# PIC32MM0064GPM036 device description
Architecture: MIPS; Family: PIC32MM1387; Series: PIC32MM
Registers are 32-bit, read-write, no defined reset value unless marked. A register's access mark holds for its fields unless they carry their own. Offsets are from the block's base; [hi:lo] are bit positions; lines under a group give offsets from that group; {n}, {i} and the like mark numbered series.

## INT
Instances: INT 0x1f802910 in periph0
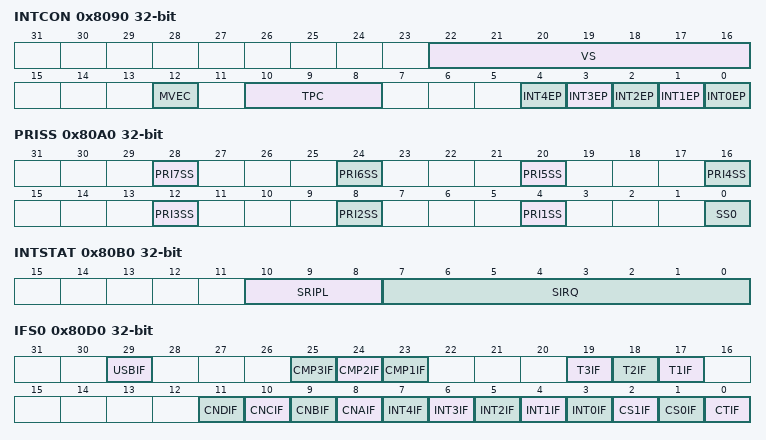
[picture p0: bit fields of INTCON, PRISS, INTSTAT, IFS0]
0x8090 INTCON — Interrupt Control Register
  [22:16] VS
  [12] MVEC — Multi Vector Configuration bit
    1=Interrupt controller configured for multi vectored mode; 0=Interrupt controller configured for single vectored mode
  [10:8] TPC — Interrupt Proximity Timer Control bits
    {v}=Interrupts of group priority {v} or lower start the Interrupt Proximity timer (v=2..7); 1=Interrupts of group priority 1 start the Interrupt Proximity timer; 0=Disables Interrupt Proximity timer
  [n] INT{n}EP (n=0..4) — External Interrupt {n} Edge
    1=Rising edge; 0=Falling edge
0x80A0 PRISS
  [4n] PRI{n}SS (n=1..7)
  [0] SS0 — Single Vector Shadow Register Set bit
    1=Single vector is presented with a shadow register set; 0=Single vector is not presented with a shadow register set
0x80B0 INTSTAT ro — Interrupt Status Register
  [10:8] SRIPL, [7:0] SIRQ
0x80C0 IPTMR
0x80D0 IFS0
  [29] USBIF, [25] CMP3IF, [24] CMP2IF, [23] CMP1IF, [19] T3IF, [18] T2IF, [17] T1IF, [11] CNDIF, [10] CNCIF, [9] CNBIF, [8] CNAIF, [n+3] INT{n}IF (n=0..4), [2] CS1IF, [1] CS0IF, [0] CTIF
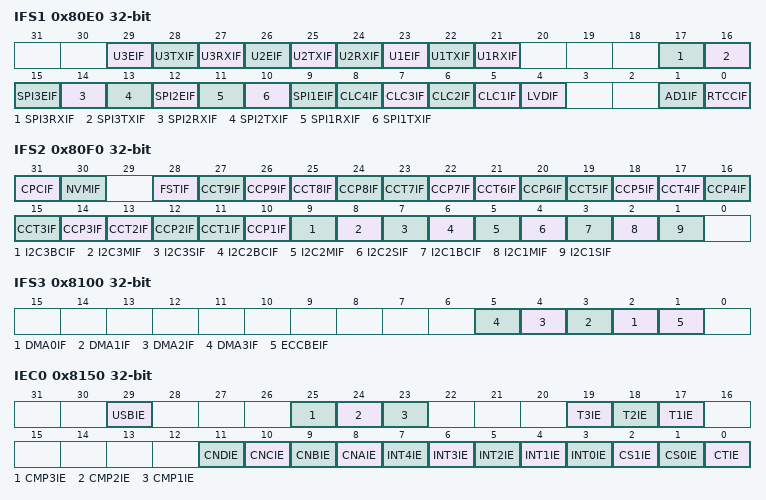
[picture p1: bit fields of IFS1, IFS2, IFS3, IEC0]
0x80E0 IFS1
  [29] U3EIF, [28] U3TXIF, [27] U3RXIF, [26] U2EIF, [25] U2TXIF, [24] U2RXIF, [23] U1EIF, [22] U1TXIF, [21] U1RXIF, [17] SPI3RXIF, [16] SPI3TXIF, [15] SPI3EIF, [14] SPI2RXIF, [13] SPI2TXIF, [12] SPI2EIF, [11] SPI1RXIF, [10] SPI1TXIF, [9] SPI1EIF, [n+4] CLC{n}IF (n=1..4), [4] LVDIF, [1] AD1IF, [0] RTCCIF
0x80F0 IFS2
  [31] CPCIF, [30] NVMIF, [28] FSTIF, [2n+9] CCT{n}IF (n=1..9), [2n+8] CCP{n}IF (n=1..9), [9] I2C3BCIF, [8] I2C3MIF, [7] I2C3SIF, [6] I2C2BCIF, [5] I2C2MIF, [4] I2C2SIF, [3] I2C1BCIF, [2] I2C1MIF, [1] I2C1SIF
0x8100 IFS3
  [n+2] DMA{n}IF (n=0..3), [1] ECCBEIF
0x8150 IEC0
  [29] USBIE, [25] CMP3IE, [24] CMP2IE, [23] CMP1IE, [19] T3IE, [18] T2IE, [17] T1IE, [11] CNDIE, [10] CNCIE, [9] CNBIE, [8] CNAIE, [n+3] INT{n}IE (n=0..4), [2] CS1IE, [1] CS0IE, [0] CTIE
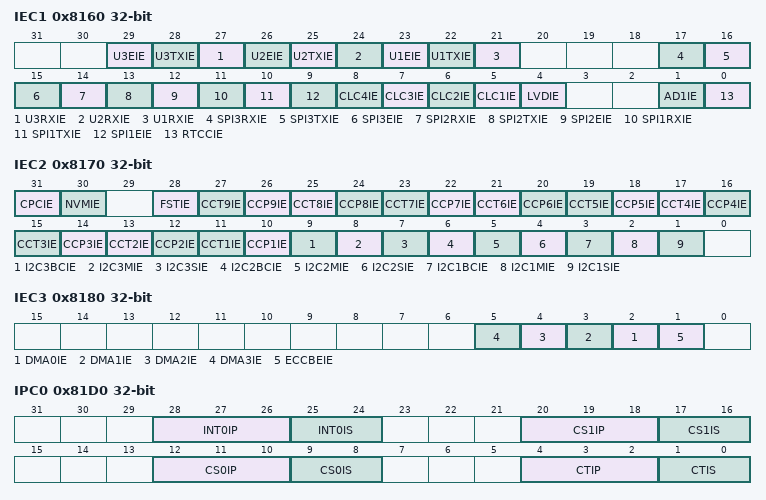
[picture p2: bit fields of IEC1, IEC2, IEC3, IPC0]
0x8160 IEC1
  [29] U3EIE, [28] U3TXIE, [27] U3RXIE, [26] U2EIE, [25] U2TXIE, [24] U2RXIE, [23] U1EIE, [22] U1TXIE, [21] U1RXIE, [17] SPI3RXIE, [16] SPI3TXIE, [15] SPI3EIE, [14] SPI2RXIE, [13] SPI2TXIE, [12] SPI2EIE, [11] SPI1RXIE, [10] SPI1TXIE, [9] SPI1EIE, [n+4] CLC{n}IE (n=1..4), [4] LVDIE, [1] AD1IE, [0] RTCCIE
0x8170 IEC2
  [31] CPCIE, [30] NVMIE, [28] FSTIE, [2n+9] CCT{n}IE (n=1..9), [2n+8] CCP{n}IE (n=1..9), [9] I2C3BCIE, [8] I2C3MIE, [7] I2C3SIE, [6] I2C2BCIE, [5] I2C2MIE, [4] I2C2SIE, [3] I2C1BCIE, [2] I2C1MIE, [1] I2C1SIE
0x8180 IEC3
  [n+2] DMA{n}IE (n=0..3), [1] ECCBEIE
0x81D0 IPC0
  [28:26] INT0IP, [25:24] INT0IS, [20:18] CS1IP, [17:16] CS1IS, [12:10] CS0IP, [9:8] CS0IS, [4:2] CTIP, [1:0] CTIS
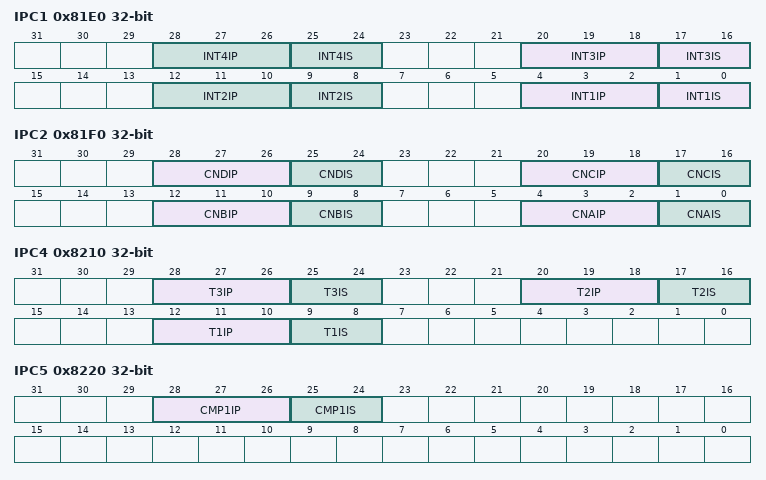
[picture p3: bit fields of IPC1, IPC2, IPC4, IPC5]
0x81E0 IPC1
  [8n-4:8n-6] INT{n}IP (n=1..4), [8n-7:8n-8] INT{n}IS (n=1..4)
0x81F0 IPC2
  [28:26] CNDIP, [25:24] CNDIS, [20:18] CNCIP, [17:16] CNCIS, [12:10] CNBIP, [9:8] CNBIS, [4:2] CNAIP, [1:0] CNAIS
0x8200 IPC3 ro
0x8210 IPC4
  [28:26] T3IP, [25:24] T3IS, [20:18] T2IP, [17:16] T2IS, [12:10] T1IP, [9:8] T1IS
0x8220 IPC5
  [28:26] CMP1IP, [25:24] CMP1IS
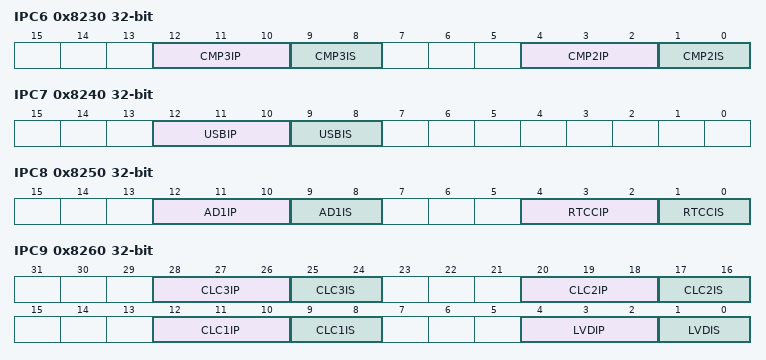
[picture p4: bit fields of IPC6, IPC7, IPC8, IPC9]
0x8230 IPC6
  [12:10] CMP3IP, [9:8] CMP3IS, [4:2] CMP2IP, [1:0] CMP2IS
0x8240 IPC7
  [12:10] USBIP, [9:8] USBIS
0x8250 IPC8
  [12:10] AD1IP, [9:8] AD1IS, [4:2] RTCCIP, [1:0] RTCCIS
0x8260 IPC9
  [28:26] CLC3IP, [25:24] CLC3IS, [20:18] CLC2IP, [17:16] CLC2IS, [12:10] CLC1IP, [9:8] CLC1IS, [4:2] LVDIP, [1:0] LVDIS
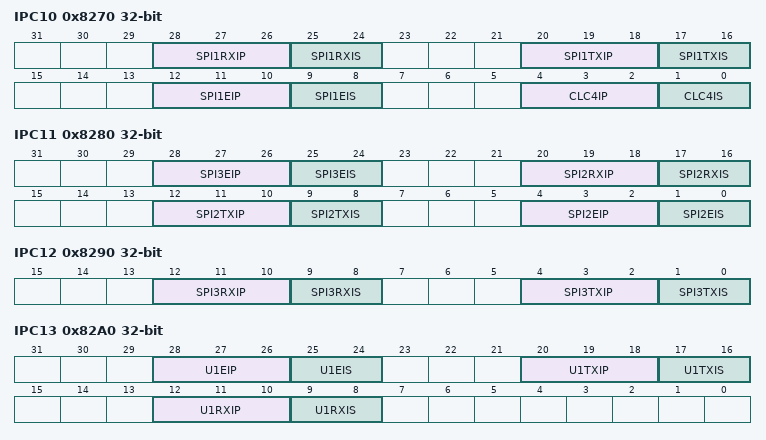
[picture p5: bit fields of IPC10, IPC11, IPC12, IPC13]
0x8270 IPC10
  [28:26] SPI1RXIP, [25:24] SPI1RXIS, [20:18] SPI1TXIP, [17:16] SPI1TXIS, [12:10] SPI1EIP, [9:8] SPI1EIS, [4:2] CLC4IP, [1:0] CLC4IS
0x8280 IPC11
  [28:26] SPI3EIP, [25:24] SPI3EIS, [20:18] SPI2RXIP, [17:16] SPI2RXIS, [12:10] SPI2TXIP, [9:8] SPI2TXIS, [4:2] SPI2EIP, [1:0] SPI2EIS
0x8290 IPC12
  [12:10] SPI3RXIP, [9:8] SPI3RXIS, [4:2] SPI3TXIP, [1:0] SPI3TXIS
0x82A0 IPC13
  [28:26] U1EIP, [25:24] U1EIS, [20:18] U1TXIP, [17:16] U1TXIS, [12:10] U1RXIP, [9:8] U1RXIS
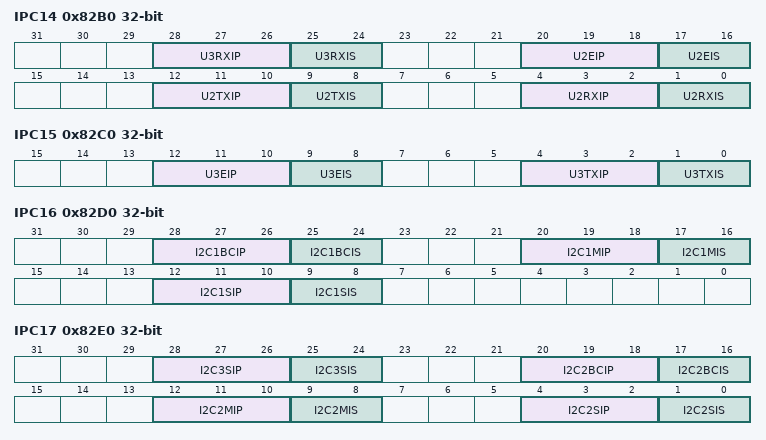
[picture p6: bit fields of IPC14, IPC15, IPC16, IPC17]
0x82B0 IPC14
  [28:26] U3RXIP, [25:24] U3RXIS, [20:18] U2EIP, [17:16] U2EIS, [12:10] U2TXIP, [9:8] U2TXIS, [4:2] U2RXIP, [1:0] U2RXIS
0x82C0 IPC15
  [12:10] U3EIP, [9:8] U3EIS, [4:2] U3TXIP, [1:0] U3TXIS
0x82D0 IPC16
  [28:26] I2C1BCIP, [25:24] I2C1BCIS, [20:18] I2C1MIP, [17:16] I2C1MIS, [12:10] I2C1SIP, [9:8] I2C1SIS
0x82E0 IPC17
  [28:26] I2C3SIP, [25:24] I2C3SIS, [20:18] I2C2BCIP, [17:16] I2C2BCIS, [12:10] I2C2MIP, [9:8] I2C2MIS, [4:2] I2C2SIP, [1:0] I2C2SIS
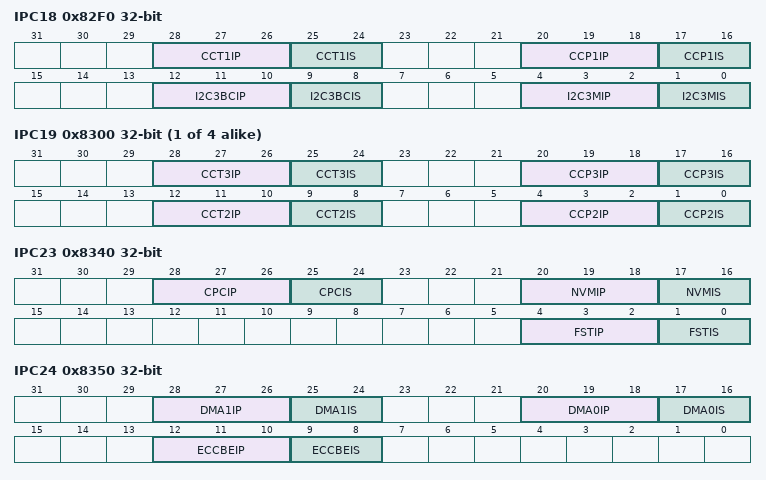
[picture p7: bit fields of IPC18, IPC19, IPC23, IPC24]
0x82F0 IPC18
  [28:26] CCT1IP, [25:24] CCT1IS, [20:18] CCP1IP, [17:16] CCP1IS, [12:10] I2C3BCIP, [9:8] I2C3BCIS, [4:2] I2C3MIP, [1:0] I2C3MIS
{0x81D0+0x10*i} IPC{i} (i=19..22)
  [28:26] CCT{2i-35}IP, [25:24] CCT{2i-35}IS, [20:18] CCP{2i-35}IP, [17:16] CCP{2i-35}IS, [12:10] CCT{2i-36}IP, [9:8] CCT{2i-36}IS, [4:2] CCP{2i-36}IP, [1:0] CCP{2i-36}IS
0x8340 IPC23
  [28:26] CPCIP, [25:24] CPCIS, [20:18] NVMIP, [17:16] NVMIS, [4:2] FSTIP, [1:0] FSTIS
0x8350 IPC24
  [28:26] DMA1IP, [25:24] DMA1IS, [20:18] DMA0IP, [17:16] DMA0IS, [12:10] ECCBEIP, [9:8] ECCBEIS
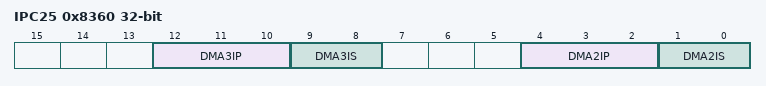
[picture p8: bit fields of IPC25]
0x8360 IPC25
  [12:10] DMA3IP, [9:8] DMA3IS, [4:2] DMA2IP, [1:0] DMA2IS
